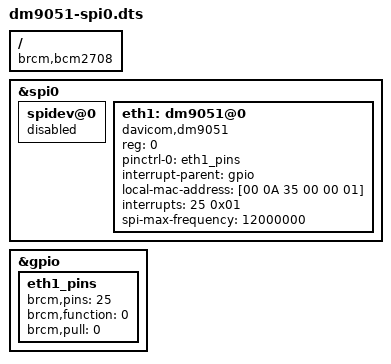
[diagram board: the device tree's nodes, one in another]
// Overlay for the davicom dm9051 Ethernet Controller
/dts-v1/;
/plugin/;

/ {
    compatible = "brcm,bcm2708";

    fragment@0 {
        target = <&spi0>;
        __overlay__ {
            /* needed to avoid dtc warning */
            #address-cells = <1>;
            #size-cells = <0>;

            status = "okay";

            //disable spidev on spi0.0
            spidev@0{
                status = "disabled";
            };

            eth1:dm9051@0{
                compatible = "davicom,dm9051";
                reg = <0>; /* CE2 */
                pinctrl-names = "default";
                pinctrl-0 = <&eth1_pins>;
                interrupt-parent = <&gpio>;
                //mac-address = [000a35000001];
                local-mac-address = [00 0A 35 00 00 01];
                interrupts = <25 0x01>; /*  gpio 25, 0x01, 0x03, 0x04 都可使用。
                                            IRQ_TYPE_NONE         = 0x00000000,
                                            IRQ_TYPE_EDGE_RISING  = 0x00000001,
                                            IRQ_TYPE_EDGE_FALLING = 0x00000002,
                                            IRQ_TYPE_EDGE_BOTH    = (IRQ_TYPE_EDGE_FALLING | IRQ_TYPE_EDGE_RISING),
                                            IRQ_TYPE_LEVEL_HIGH   = 0x00000004,
                                            IRQ_TYPE_LEVEL_LOW    = 0x00000008,
                                            IRQ_TYPE_LEVEL_MASK   = (IRQ_TYPE_LEVEL_LOW | IRQ_TYPE_LEVEL_HIGH),
                                            IRQ_TYPE_SENSE_MASK   = 0x0000000f,
                                            IRQ_TYPE_DEFAULT      = IRQ_TYPE_SENSE_MASK,
                                        */
                spi-max-frequency = <12000000>;
                status = "okay";
            };
        };
    };

    fragment@1 {
        target = <&gpio>;

        __overlay__ {
            eth1_pins: eth1_pins {
                brcm,pins = <25>;
                brcm,function = <0>; /* in */
                brcm,pull = <0>; /* none */
            };
        };
    };

    // disable spi-dev on spi1.0
    /*fragment@2 {
        target = <&spidev0>;

        __overlay__ {
            status = "disabled";
        };
    };*/

    __overrides__ {
        int_pin = <&eth1>, "interrupts:0",
                  <&eth1_pins>, "brcm,pins:0";
        speed   = <&eth1>, "spi-max-frequency:0";
    };
};
